# cc13x2_cc26x2 register map
File version: 2.1
CPU: CM4 r0p1, little endian, MPU, FPU, 3 interrupt priority bits
Registers are 32-bit, read-write, reset 0x0 unless marked. A register's access mark holds for its fields unless they carry their own. Offsets are from the block's base; [hi:lo] are bit positions; {n}, {i} and the like mark numbered series; 'fields as' and 'values as' point back to an identical list.

## CPU_TIPROP — Cortex-M's TI proprietary registers
Base 0xE00FE000
0xFF8 TRACECLKMUX — Internal. Only to be used through TI provided API.
  [0] TRACECLK_N_SWV

## CPU_TPIU — Cortex-M's Trace Port Interface Unit (TPIU)
Base 0xE0040000
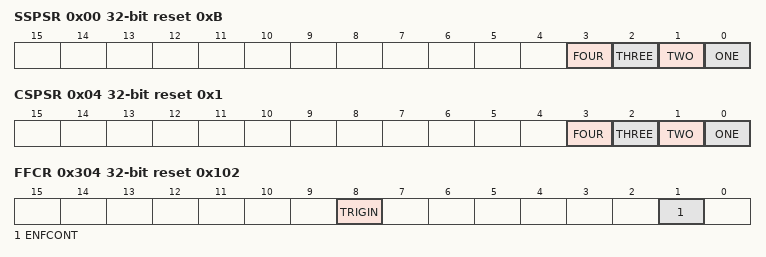
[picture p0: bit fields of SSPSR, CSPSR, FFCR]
0x00 SSPSR ro reset 0xB — Supported Sync Port Sizes his register represents a single port size that is supported on the device, that is, 4, 2 or 1. This is to ensure that tools do not attempt to select a port width that an attached TPA cannot capture.
  [3] FOUR, [2] THREE, [1] TWO, [0] ONE
0x04 CSPSR reset 0x1 — Current Sync Port Size his register has the same format as SSPSR but only one bit can be set, and all others must be zero. Writing values with more than one bit set, or setting a bit that is not indicated as supported can cause Unpredictable behavior. On reset this defaults to the smallest possible port size, 1 bit.
  [3] FOUR, [2] THREE, [1] TWO, [0] ONE
0x10 ACPR — Async Clock Prescaler his register scales the baud rate of the asynchronous output.
  [12:0] PRESCALER
0xF0 SPPR reset 0x1 — Selected Pin Protocol his register selects the protocol to be used for trace output. ote: If this register is changed while trace data is being output, data corruption occurs.
  [1:0] PROTOCOL
0x300 FFSR ro reset 0x8 — Formatter and Flush Status
  [3] FTNONSTOP
0x304 FFCR reset 0x102 — Formatter and Flush Control hen one of the two single wire output (SWO) modes is selected, ENFCONT enables the formatter to be bypassed. If the formatter is bypassed, only the ITM/DWT trace source (ATDATA2) passes through. The TPIU accepts and discards data that is presented on the ETM port (ATDATA1). This function is intended to be used when it is necessary to connect a device containing an ETM to a trace capture device that is only able to capture Serial Wire Output (SWO) data. Enabling or disabling the formatter causes momentary data corruption. ote: If the selected pin protocol register (SPPR.PROTOCOL) is set to 0x00 (TracePort mode), this register always reads 0x102, because the formatter is automatically enabled. If one of the serial wire modes is then selected, the register reverts to its previously programmed value.
  [8] TRIGIN, [1] ENFCONT
0x308 FSCR ro — Formatter Synchronization Counter
0xFA0 CLAIMMASK ro reset 0xF — Claim Tag Mask
0xFA0 CLAIMSET wo reset 0xF — Claim Tag Set
0xFA4 CLAIMTAG ro — Current Claim Tag
0xFA4 CLAIMCLR wo — Claim Tag Clear
0xFC8 DEVID ro reset 0xCA0 — Device ID

## PKA_INT — Integrated module which includes the PKA K
Base 0x40027000
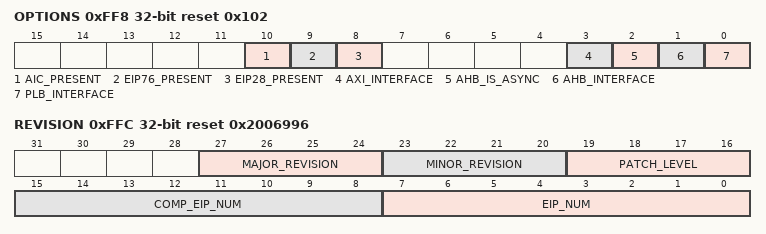
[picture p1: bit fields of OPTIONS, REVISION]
0xFF8 OPTIONS ro reset 0x102 — PKA Options register
  [10] AIC_PRESENT, [9] EIP76_PRESENT, [8] EIP28_PRESENT, [3] AXI_INTERFACE, [2] AHB_IS_ASYNC, [1] AHB_INTERFACE, [0] PLB_INTERFACE
0xFFC REVISION ro reset 0x2006996 — PKA hardware revision register his register allows the host access to the hardware revision number of the PKA engine for software driver matching and diagnostic purposes. It is always located at the highest address in the access space of the module and contains an encoding of the EIP number (with its complement as signature) for recognition of the hardware module.
  [27:24] MAJOR_REVISION, [23:20] MINOR_REVISION, [19:16] PATCH_LEVEL, [15:8] COMP_EIP_NUM, [7:0] EIP_NUM

## PKA_RAM — This is the a SRAM within the PKA domain, intended for PKA usage only.
Base 0x40026000
{0x0+4i} BANK0{i} (i=0..511) — PKA RAM
  [31:0] DATA

## RFC_DBELL — RF core doorbell he doorbell module is the main user interface to the radio sub-system. It contains the registers used for both submitting commands to the radio, and for configuring radio interrupts from the RF core.
Base 0x40041000
0x00 CMDR — Doorbell Command Register
  [31:0] CMD
0x04 CMDSTA ro — Doorbell Command Status Register
  [31:0] STAT
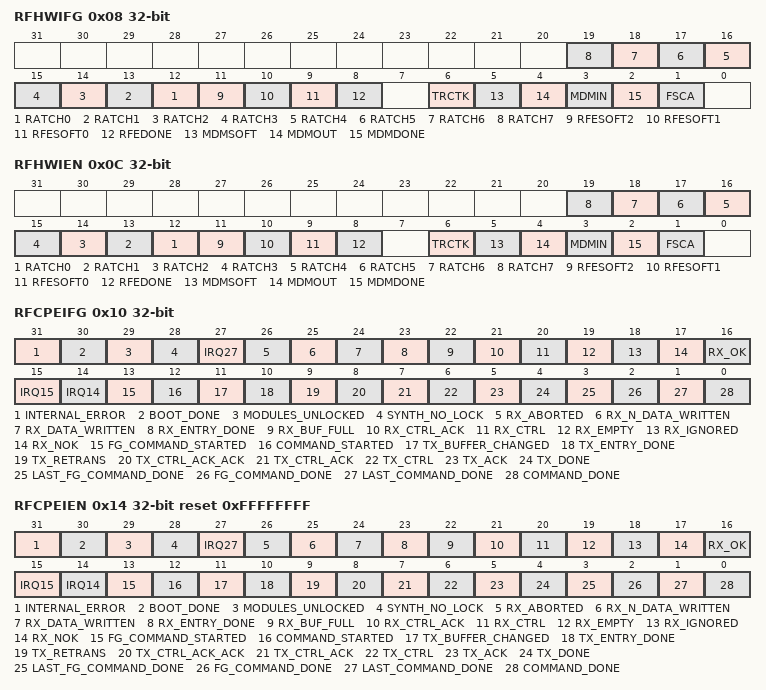
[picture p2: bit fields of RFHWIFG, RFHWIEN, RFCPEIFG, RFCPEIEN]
0x08 RFHWIFG — Interrupt Flags From RF Hardware Modules
  [n+12] RATCH{n} (n=0..7), [11] RFESOFT2, [10] RFESOFT1, [9] RFESOFT0, [8] RFEDONE, [6] TRCTK, [5] MDMSOFT, [4] MDMOUT, [3] MDMIN, [2] MDMDONE, [1] FSCA
0x0C RFHWIEN — Interrupt Enable For RF Hardware Modules
  fields as RFHWIFG
0x10 RFCPEIFG — Interrupt Flags For Command and Packet Engine Generated Interrupts
  [31] INTERNAL_ERROR, [30] BOOT_DONE, [29] MODULES_UNLOCKED, [28] SYNTH_NO_LOCK, [27] IRQ27, [26] RX_ABORTED, [25] RX_N_DATA_WRITTEN, [24] RX_DATA_WRITTEN, [23] RX_ENTRY_DONE, [22] RX_BUF_FULL, [21] RX_CTRL_ACK, [20] RX_CTRL, [19] RX_EMPTY, [18] RX_IGNORED, [17] RX_NOK, [16] RX_OK, [15] IRQ15, [14] IRQ14, [13] FG_COMMAND_STARTED, [12] COMMAND_STARTED, [11] TX_BUFFER_CHANGED, [10] TX_ENTRY_DONE, [9] TX_RETRANS, [8] TX_CTRL_ACK_ACK, [7] TX_CTRL_ACK, [6] TX_CTRL, [5] TX_ACK, [4] TX_DONE, [3] LAST_FG_COMMAND_DONE, [2] FG_COMMAND_DONE, [1] LAST_COMMAND_DONE, [0] COMMAND_DONE
0x14 RFCPEIEN reset 0xFFFFFFFF — Interrupt Enable For Command and Packet Engine Generated Interrupts
  fields as RFCPEIFG
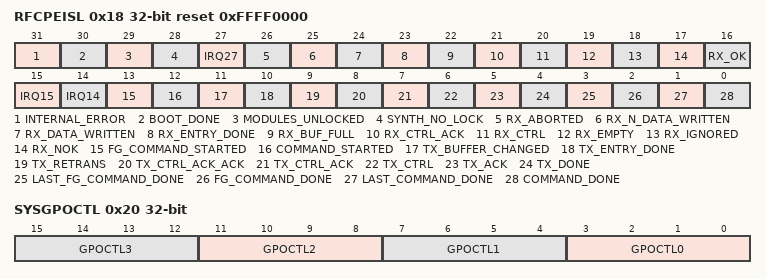
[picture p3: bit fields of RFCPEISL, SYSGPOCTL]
0x18 RFCPEISL reset 0xFFFF0000 — Interrupt Vector Selection For Command and Packet Engine Generated Interrupts
  fields as RFCPEIFG
0x1C RFACKIFG — Doorbell Command Acknowledgement Interrupt Flag
  [0] ACKFLAG
0x20 SYSGPOCTL — RF Core General Purpose Output Control
  [4n+3:4n] GPOCTL{n} (n=0..3)
